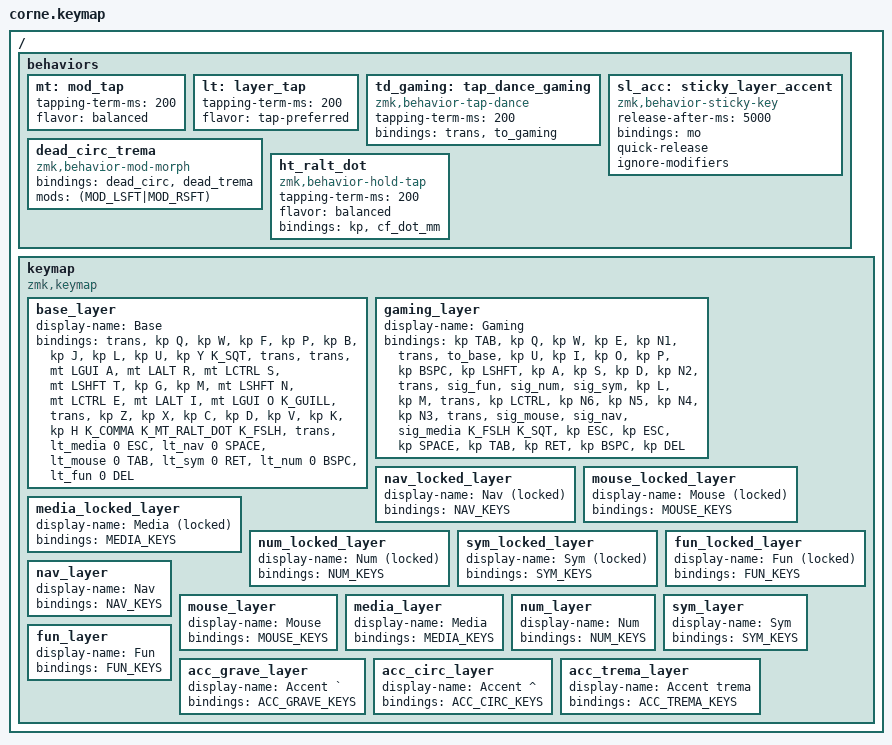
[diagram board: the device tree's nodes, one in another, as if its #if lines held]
/*
 * Copyright (c) 2020 The ZMK Contributors
 *
 * SPDX-License-Identifier: MIT
 */

#include <behaviors.dtsi>
#include <dt-bindings/zmk/bt.h>
#include <dt-bindings/zmk/keys.h>
#include <dt-bindings/zmk/outputs.h>
#include <dt-bindings/zmk/pointing.h>
#include <behaviors/mouse_keys.dtsi>
#include "locale.h"  // K_* character keys for the US or Canadian French layout

// Layer numbers. When several layers are active, ZMK uses the highest number first, so:
//   - Gaming sits low, so layers held from Gaming (Fun, Num...) work on top of it.
//   - Each layer has a "locked" copy below the held layers. "Lock X" switches to the copy,
//     so releasing the thumb key (which turns off the held layer) doesn't undo the lock,
//     and a layer held on top of a locked one still wins.
#define BASE     0
#define GAMING   1
#define NAV_L    2
#define MOUSE_L  3
#define MEDIA_L  4
#define NUM_L    5
#define SYM_L    6
#define FUN_L    7
#define NAV      8
#define MOUSE    9
#define MEDIA   10
#define NUM     11
#define SYM     12
#define FUN     13
// Accent layers: one-shot ("sticky"), active for the next key only, like dead keys.
#define ACC_GRAVE 14
#define ACC_CIRC  15
#define ACC_TREMA 16

/ {
    behaviors {
        mt: mod_tap {
            tapping-term-ms = <200>;
            flavor = "balanced"; // Great flavor for typing home-row mods smoothly
        };

        lt: layer_tap {
            tapping-term-ms = <200>;
            flavor = "tap-preferred";
        };

        td_gaming: tap_dance_gaming {
            compatible = "zmk,behavior-tap-dance";
            #binding-cells = <0>;
            tapping-term-ms = <200>; // Time window to register the second tap (in milliseconds)
            bindings = <&trans>, <&to_gaming>;
        };

        // ---- Layer signals for the PC layer display (tools/layer_overlay.pyw) ----
        // Holding a layer also holds an unused F-key; lock keys tap F21 then that layer's key.
        // The display swallows these keys, so other apps never see them.
        //   held:  F13 Nav  F14 Media  F15 Num  F16 Sym  F17 Fun  F18 Mouse
        //   lock:  F21 + the layer's held key    to Base: F19    to Gaming: F20
#define SIG_MO(name, layer, key) \
        name: name { \
            compatible = "zmk,behavior-macro"; \
            #binding-cells = <0>; \
            wait-ms = <0>; \
            tap-ms = <0>; \
            bindings = <&macro_press &mo layer &kp key>, <&macro_pause_for_release>, <&macro_release &kp key &mo layer>; \
        };
#define SIG_LT(name, hold_macro) \
        name: name { \
            compatible = "zmk,behavior-hold-tap"; \
            #binding-cells = <2>; \
            tapping-term-ms = <200>; \
            flavor = "tap-preferred"; \
            bindings = <&hold_macro>, <&kp>; \
        };
#define SIG_TO(name, layer, key) \
        name: name { \
            compatible = "zmk,behavior-macro"; \
            #binding-cells = <0>; \
            wait-ms = <30>; \
            tap-ms = <30>; \
            bindings = <&macro_tap &to layer &kp key>; \
        };
#define SIG_LOCK(name, layer, key) \
        name: name { \
            compatible = "zmk,behavior-macro"; \
            #binding-cells = <0>; \
            wait-ms = <30>; \
            tap-ms = <30>; \
            bindings = <&macro_tap &to layer &kp F21 &kp key>; \
        };

        SIG_MO(sig_nav,   NAV,   F13)
        SIG_MO(sig_media, MEDIA, F14)
        SIG_MO(sig_num,   NUM,   F15)
        SIG_MO(sig_sym,   SYM,   F16)
        SIG_MO(sig_fun,   FUN,   F17)
        SIG_MO(sig_mouse, MOUSE, F18)

        // Thumb layer-taps: tap = key, hold = layer + signal. Use as &lt_nav 0 SPACE.
        SIG_LT(lt_nav,   sig_nav)
        SIG_LT(lt_media, sig_media)
        SIG_LT(lt_num,   sig_num)
        SIG_LT(lt_sym,   sig_sym)
        SIG_LT(lt_fun,   sig_fun)
        SIG_LT(lt_mouse, sig_mouse)

        // Locks go to the locked copies.
        SIG_TO(to_base,     BASE,    F19)
        SIG_TO(to_gaming,   GAMING,  F20)
        SIG_LOCK(to_nav,    NAV_L,   F13)
        SIG_LOCK(to_media,  MEDIA_L, F14)
        SIG_LOCK(to_num,    NUM_L,   F15)
        SIG_LOCK(to_sym,    SYM_L,   F16)
        SIG_LOCK(to_fun,    FUN_L,   F17)
        SIG_LOCK(to_mouse,  MOUSE_L, F18)

        // ---- French characters ----
        // Typed with Windows Alt codes (hold Alt, type 4 digits on the keypad; needs Num Lock on,
        // Windows only). FR_CHAR gives the lowercase code normally and the capital with Shift.
#define ALT_CODE(name, a, b, c, d) \
        name: name { \
            compatible = "zmk,behavior-macro"; \
            #binding-cells = <0>; \
            wait-ms = <15>; \
            tap-ms = <15>; \
            bindings = <&macro_press &kp LALT>, \
                       <&macro_tap &kp KP_N##a &kp KP_N##b &kp KP_N##c &kp KP_N##d>, \
                       <&macro_release &kp LALT>; \
        };
#define FR_CHAR(name, a, b, c, d, A, B, C, D) \
        ALT_CODE(name##_lo, a, b, c, d) \
        ALT_CODE(name##_up, A, B, C, D) \
        name: name { \
            compatible = "zmk,behavior-mod-morph"; \
            #binding-cells = <0>; \
            bindings = <&name##_lo>, <&name##_up>; \
            mods = <(MOD_LSFT|MOD_RSFT)>; \
        };

        FR_CHAR(fr_e_acute, 0,2,3,3, 0,2,0,1)   // é É
        FR_CHAR(fr_c_cedil, 0,2,3,1, 0,1,9,9)   // ç Ç
        FR_CHAR(fr_guill,   0,1,7,1, 0,1,8,7)   // « »
        FR_CHAR(fr_a_grave, 0,2,2,4, 0,1,9,2)   // à À
        FR_CHAR(fr_e_grave, 0,2,3,2, 0,2,0,0)   // è È
        FR_CHAR(fr_u_grave, 0,2,4,9, 0,2,1,7)   // ù Ù
        FR_CHAR(fr_a_circ,  0,2,2,6, 0,1,9,4)   // â Â
        FR_CHAR(fr_e_circ,  0,2,3,4, 0,2,0,2)   // ê Ê
        FR_CHAR(fr_i_circ,  0,2,3,8, 0,2,0,6)   // î Î
        FR_CHAR(fr_o_circ,  0,2,4,4, 0,2,1,2)   // ô Ô
        FR_CHAR(fr_u_circ,  0,2,5,1, 0,2,1,9)   // û Û
        FR_CHAR(fr_e_trema, 0,2,3,5, 0,2,0,3)   // ë Ë
        FR_CHAR(fr_i_trema, 0,2,3,9, 0,2,0,7)   // ï Ï
        FR_CHAR(fr_u_trema, 0,2,5,2, 0,2,2,0)   // ü Ü
        FR_CHAR(fr_y_trema, 0,2,5,5, 0,1,5,9)   // ÿ Ÿ
        ALT_CODE(fr_trema,  0,1,6,8)            // ¨ on its own

        // Dead keys: tap the accent, then the letter. The accent layer lasts for one key
        // (Shift and other modifiers don't use it up) or 5 s. Accent then Space = the accent itself.
        // Signals for the layer display: F22 grave, F23 circumflex, F24 tréma.
        sl_acc: sticky_layer_accent {
            compatible = "zmk,behavior-sticky-key";
            #binding-cells = <1>;
            release-after-ms = <5000>;
            bindings = <&mo>;
            quick-release;
            ignore-modifiers;
        };
#define DEAD_KEY(name, layer, key) \
        name: name { \
            compatible = "zmk,behavior-macro"; \
            #binding-cells = <0>; \
            wait-ms = <0>; \
            tap-ms = <10>; \
            bindings = <&macro_tap &kp key &sl_acc layer>; \
        };
        DEAD_KEY(dead_grave, ACC_GRAVE, F22)
        DEAD_KEY(dead_circ,  ACC_CIRC,  F23)
        DEAD_KEY(dead_trema, ACC_TREMA, F24)
        dead_circ_trema: dead_circ_trema {   // ^ normally, ¨ with Shift
            compatible = "zmk,behavior-mod-morph";
            #binding-cells = <0>;
            bindings = <&dead_circ>, <&dead_trema>;
            mods = <(MOD_LSFT|MOD_RSFT)>;
        };

        // ---- Layout variant helpers (see locale.h, generated by tools/gen_locale.py) ----
#define CF_DEAD_SPACE(name, key)         name: name {             compatible = "zmk,behavior-macro";             #binding-cells = <0>;             wait-ms = <0>;             tap-ms = <10>;             bindings = <&macro_tap &kp key &kp SPACE>;         };
#define CF_SHIFT_MORPH(name, normal, shifted)         name: name {             compatible = "zmk,behavior-mod-morph";             #binding-cells = <0>;             bindings = <normal>, <shifted>;             mods = <(MOD_LSFT|MOD_RSFT)>;         };
#define CF_TAP2(name, a, b)         name: name {             compatible = "zmk,behavior-macro";             #binding-cells = <0>;             wait-ms = <0>;             tap-ms = <10>;             bindings = <&macro_tap a b>;         };
        LOCALE_BEHAVIORS
#if defined(LAYOUT_CA_FR)
        // Dead keys send Windows' own Canadian French dead key, then the display signal
        // (after the dead key, so the display's "next key" check doesn't end it at once).
        CF_TAP2(cf_dead_grave, &kp SQT, &kp F22)
        CF_TAP2(cf_dead_circ,  &kp LBKT, &kp F23)
        CF_TAP2(cf_dead_trema, &kp LS(RBKT), &kp F24)
        CF_SHIFT_MORPH(cf_dead_circ_trema, &cf_dead_circ, &cf_dead_trema)
        CF_TAP2(cf_c_cedil_lo, &kp RBKT, &kp C)       // dead ¸ then c = ç
        CF_TAP2(cf_c_cedil_up, &kp RBKT, &kp LS(C))   // Ç
        CF_SHIFT_MORPH(cf_c_cedil, &cf_c_cedil_lo, &cf_c_cedil_up)
        ht_ralt_dot: ht_ralt_dot {   // like &mt RALT DOT, but the tap keeps Shift+. = >
            compatible = "zmk,behavior-hold-tap";
            #binding-cells = <2>;
            tapping-term-ms = <200>;
            flavor = "balanced";
            bindings = <&kp>, <&cf_dot_mm>;
        };
#endif
    };
};

// ---- Keys that differ between the US and Canadian French builds ----
#if defined(LAYOUT_CA_FR)
#define K_DEAD_GRAVE       &cf_dead_grave       // Windows' own dead keys
#define K_DEAD_CIRC_TREMA  &cf_dead_circ_trema
#define K_E_ACUTE          &kp FSLH             // é key; Shift gives É
#define K_C_CEDIL          &cf_c_cedil
#define K_GUILL            &kp NON_US_BSLH      // « ; Shift gives »
#define K_MT_RALT_DOT      &ht_ralt_dot RALT 0
#else
#define K_DEAD_GRAVE       &dead_grave          // one-shot accent layers + Alt codes
#define K_DEAD_CIRC_TREMA  &dead_circ_trema
#define K_E_ACUTE          &fr_e_acute
#define K_C_CEDIL          &fr_c_cedil
#define K_GUILL            &fr_guill
#define K_MT_RALT_DOT      &mt RALT DOT
#endif

// ---- Layer contents. Each one is used twice: held layer and locked copy. ----

#define NAV_KEYS \
&trans  &bootloader  &td_gaming  &trans     &trans     &trans    &trans      &trans    &trans     &trans     &trans     &trans \
&trans  &kp LGUI     &kp LALT    &kp LCTRL  &kp LSHFT  &trans    &caps_word  &kp LEFT  &kp DOWN   &kp UP     &kp RIGHT  &trans \
&trans  &trans       &kp RALT    &to_num    &to_nav    &trans    &kp INS     &kp HOME  &kp PG_DN  &kp PG_UP  &kp END    &trans \
                                 &trans     &trans     &trans    &kp RET     &kp BSPC  &kp DEL

#define MOUSE_KEYS \
&kp TAB    &bootloader  &trans    &trans     &trans      &trans    &trans     &trans          &trans          &trans        &trans           &kp BSPC \
&kp LCTRL  &kp LGUI     &kp LALT  &kp LCTRL  &kp LSHFT   &trans    &trans     &mmv MOVE_LEFT  &mmv MOVE_DOWN  &mmv MOVE_UP  &mmv MOVE_RIGHT  &trans \
&kp LSHFT  &trans       &kp RALT  &to_sym    &to_mouse   &trans    &trans     &msc SCRL_LEFT  &msc SCRL_DOWN  &msc SCRL_UP  &msc SCRL_RIGHT  &kp ESC \
                                  &trans     &trans      &trans    &mkp RCLK  &mkp LCLK       &mkp MCLK

#define MEDIA_KEYS \
&trans  &bootloader  &trans    &trans     &trans     &trans    &trans        &trans        &trans        &trans        &trans        &trans \
&trans  &kp LGUI     &kp LALT  &kp LCTRL  &kp LSHFT  &trans    &out OUT_USB  &kp C_PREV    &kp C_VOL_DN  &kp C_VOL_UP  &kp C_NEXT    &trans \
&trans  &trans       &kp RALT  &to_fun    &to_media  &trans    &out OUT_BLE  &bt BT_SEL 0  &bt BT_SEL 1  &bt BT_SEL 2  &bt BT_SEL 3  &trans \
                               &trans     &trans     &trans    &kp C_STOP    &kp C_PP      &kp C_MUTE

#define NUM_KEYS \
&trans  K_LBKT   K_N7  K_N8   K_N9  K_RBKT     &trans  &to_base   &trans     &td_gaming  &bootloader  &trans \
&trans  K_SEMI   K_N4  K_N5   K_N6  K_EQUAL    &trans  &kp LSHFT  &kp LCTRL  &kp LALT    &kp LGUI     &trans \
&trans  K_GRAVE  K_N1  K_N2   K_N3  K_BSLH     &trans  &to_num    &to_nav    &kp RALT    &trans       &trans \
                           K_DOT  K_N0  K_MINUS    &trans  &trans     &trans

#define SYM_KEYS \
&trans  K_LBRC   K_LT       K_GT       K_DQT           K_RBRC  &trans  &to_base   &trans     &td_gaming  &bootloader  &trans \
&trans  K_COLON  K_DEAD_GRAVE  K_E_ACUTE  K_DEAD_CIRC_TREMA  K_PLUS  &trans  &kp LSHFT  &kp LCTRL  &kp LALT    &kp LGUI     &trans \
&trans  K_TILDE  K_C_CEDIL  K_QMARK    K_SQT           K_PIPE  &trans  &to_sym    &to_mouse  &kp RALT    &trans       &trans \
                             K_LPAR   K_RPAR   K_UNDER    &trans  &trans     &trans

#define FUN_KEYS \
&trans  &kp F12  &kp F7  &kp F8     &kp F9     &kp PSCRN          &trans  &to_base   &trans     &td_gaming  &bootloader  &trans \
&trans  &kp F11  &kp F4  &kp F5     &kp F6     &kp SLCK           &trans  &kp LSHFT  &kp LCTRL  &kp LALT    &kp LGUI     &trans \
&trans  &kp F10  &kp F1  &kp F2     &kp F3     &kp PAUSE_BREAK    &trans  &to_fun    &to_media  &kp RALT    &trans       &trans \
                         &kp K_APP  &kp SPACE  &kp TAB            &trans  &trans     &trans

// Accent layers (one key only, after a dead key). Generated layout: letters as on Base.
#define ACC_GRAVE_KEYS \
&trans      &trans      &trans      &trans      &trans      &trans      &trans      &trans      &fr_u_grave &trans      &trans      &trans \
&trans      &fr_a_grave &trans      &trans      &trans      &trans      &trans      &trans      &fr_e_grave &trans      &trans      &trans \
&trans      &trans      &trans      &trans      &trans      &trans      &trans      &trans      &trans      &trans      &trans      &trans \
                                    &trans      &kp GRAVE   &trans      &trans      &trans      &trans

#define ACC_CIRC_KEYS \
&trans     &trans     &trans     &trans     &trans     &trans     &trans     &trans     &fr_u_circ &trans     &trans     &trans \
&trans     &fr_a_circ &trans     &trans     &trans     &trans     &trans     &trans     &fr_e_circ &fr_i_circ &fr_o_circ &trans \
&trans     &trans     &trans     &trans     &trans     &trans     &trans     &trans     &trans     &trans     &trans     &trans \
                                 &trans     &kp CARET  &trans     &trans     &trans     &trans

#define ACC_TREMA_KEYS \
&trans      &trans      &trans      &trans      &trans      &trans      &trans      &trans      &fr_u_trema &fr_y_trema &trans      &trans \
&trans      &trans      &trans      &trans      &trans      &trans      &trans      &trans      &fr_e_trema &fr_i_trema &trans      &trans \
&trans      &trans      &trans      &trans      &trans      &trans      &trans      &trans      &trans      &trans      &trans      &trans \
                                    &trans      &fr_trema   &trans      &trans      &trans      &trans

/ {
    keymap {
        compatible = "zmk,keymap";

        // Node order must match the layer numbers above.

        base_layer {
            display-name = "Base";

            // -----------------------------------------------------------------------------------------
            // |  |  Q  |  W  |  F  |  P  |  B  |   |  J  |  L   |  U  |  Y  |  '  |  |
            // |  | A/G | R/A | S/C | T/S |  G  |   |  M  | N/S  | E/C | I/A | O/G |    |
            // |  |  Z  |  X  |  C  |  D  |  V  |   |  K  |  H   |  ,  |  .  |     | Studio |
            //                    | ESC | SPC | TAB |   | RET | BKSP | DEL |

            bindings = <
&trans  &kp Q        &kp W       &kp F          &kp P          &kp B     &kp J  &kp L         &kp U        &kp Y         K_SQT       &trans
&trans  &mt LGUI A   &mt LALT R  &mt LCTRL S    &mt LSHFT T    &kp G     &kp M  &mt LSHFT N   &mt LCTRL E  &mt LALT I    &mt LGUI O  K_GUILL
&trans  &kp Z        &kp X       &kp C          &kp D          &kp V     &kp K  &kp H         K_COMMA      K_MT_RALT_DOT K_FSLH      &trans
                                 &lt_media 0 ESC  &lt_nav 0 SPACE  &lt_mouse 0 TAB  &lt_sym 0 RET  &lt_num 0 BSPC  &lt_fun 0 DEL
            >;
        };

        gaming_layer {
            display-name = "Gaming";

            // -----------------------------------------------------------------------------------------
            // |  TAB |  Q  |  W  |  E  |  1  |     |   | BASE|  U  |  I  |  O  |  P  | BKSP |
            // | SHFT |  A  |  S  |  D  |  2  |     |   | FUN | NUM | SYM |  L  |  M  |      |
            // | CTRL |  6  |  5  |  4  |  3  |     |   |     | NAV |MEDIA|  /  |  '  | ESC  |
            //                    | ESC | SPC | TAB |   | RET | BKSP| DEL |

            bindings = <
&kp TAB    &kp Q   &kp W   &kp E    &kp N1     &trans     &to_base   &kp U     &kp I      &kp O     &kp P    &kp BSPC
&kp LSHFT  &kp A   &kp S   &kp D    &kp N2     &trans     &sig_fun   &sig_num  &sig_sym   &kp L     &kp M    &trans
&kp LCTRL  &kp N6  &kp N5  &kp N4   &kp N3     &trans     &sig_mouse &sig_nav  &sig_media K_FSLH    K_SQT    &kp ESC
                           &kp ESC  &kp SPACE  &kp TAB    &kp RET    &kp BSPC  &kp DEL
            >;
        };

        nav_locked_layer   { display-name = "Nav (locked)";   bindings = <NAV_KEYS>; };
        mouse_locked_layer { display-name = "Mouse (locked)"; bindings = <MOUSE_KEYS>; };
        media_locked_layer { display-name = "Media (locked)"; bindings = <MEDIA_KEYS>; };
        num_locked_layer   { display-name = "Num (locked)";   bindings = <NUM_KEYS>; };
        sym_locked_layer   { display-name = "Sym (locked)";   bindings = <SYM_KEYS>; };
        fun_locked_layer   { display-name = "Fun (locked)";   bindings = <FUN_KEYS>; };

        nav_layer   { display-name = "Nav";   bindings = <NAV_KEYS>; };
        mouse_layer { display-name = "Mouse"; bindings = <MOUSE_KEYS>; };
        media_layer { display-name = "Media"; bindings = <MEDIA_KEYS>; };
        num_layer   { display-name = "Num";   bindings = <NUM_KEYS>; };
        sym_layer   { display-name = "Sym";   bindings = <SYM_KEYS>; };
        fun_layer   { display-name = "Fun";   bindings = <FUN_KEYS>; };

        acc_grave_layer { display-name = "Accent `"; bindings = <ACC_GRAVE_KEYS>; };
        acc_circ_layer  { display-name = "Accent ^"; bindings = <ACC_CIRC_KEYS>; };
        acc_trema_layer { display-name = "Accent trema"; bindings = <ACC_TREMA_KEYS>; };
    };
};
